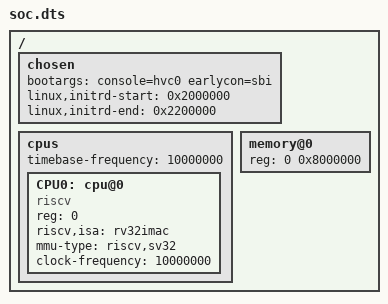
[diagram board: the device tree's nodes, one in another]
/dts-v1/;

/ {
    #address-cells = <1>;
    #size-cells = <1>;
    
    chosen {
        bootargs = "console=hvc0 earlycon=sbi";
        linux,initrd-start = <0x2000000>;
        linux,initrd-end = <0x2200000>;
    };
    
    cpus {
        #address-cells = <1>;
        #size-cells = <0>;
        timebase-frequency = <10000000>;
        CPU0: cpu@0 {
            device_type = "cpu";
            reg = <0>;
            status = "okay";
            compatible = "riscv";
            riscv,isa = "rv32imac";
            mmu-type = "riscv,sv32";
            clock-frequency = <10000000>;
        };
    };
    
    memory@0 {
        device_type = "memory";
        reg = <0 0x8000000>;
    };
};

